# N32G41x register map
Vendor: Nsingtech Ltd.; File version: 1.0
CPU: CM4 r0p1, little endian, no MPU, no FPU, 4 interrupt priority bits
Registers are 32-bit, read-write, reset 0x0 unless marked. A register's access mark holds for its fields unless they carry their own. Offsets are from the block's base; [hi:lo] are bit positions; {n}, {i} and the like mark numbered series; 'fields as' and 'values as' point back to an identical list.

## COMP — Comparator
Base 0x40002400
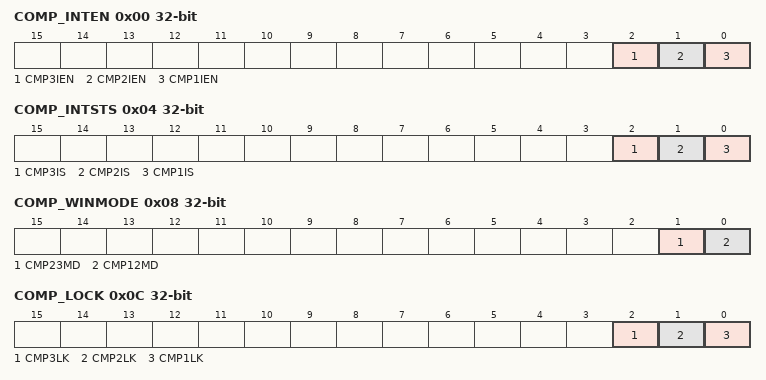
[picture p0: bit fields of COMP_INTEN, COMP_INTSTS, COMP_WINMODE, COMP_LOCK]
0x00 COMP_INTEN — COMP Interrupt Enable Register
  [2] CMP3IEN — Comparator 3 interrupt enable
  [1] CMP2IEN — Comparator 2 interrupt enable
  [0] CMP1IEN — Comparator 1 interrupt enable
0x04 COMP_INTSTS — COMP Interrupt Status Register
  [2] CMP3IS — Comparator 3 interrupt status flag, write 1 to clear
  [1] CMP2IS — Comparator 2 interrupt status flag, write 1 to clear
  [0] CMP1IS — Comparator 1 interrupt status flag, write 1 to clear
0x08 COMP_WINMODE — COMP Window Mode Register
  [1] CMP23MD — Comparator 2 and 3 window mode selection
  [0] CMP12MD — Comparator 1 and 2 window mode selection
0x0C COMP_LOCK
  [2] CMP3LK — Comparator 3 lock bit
  [1] CMP2LK — Comparator 2 lock bit
  [0] CMP1LK — Comparator 1 lock bit
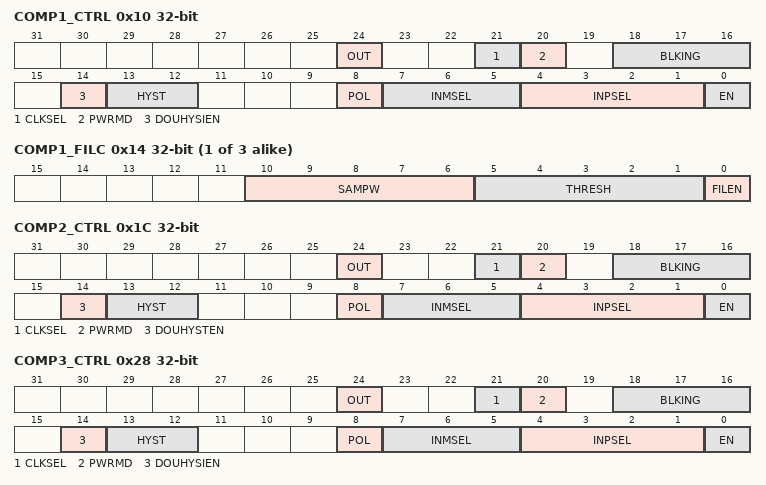
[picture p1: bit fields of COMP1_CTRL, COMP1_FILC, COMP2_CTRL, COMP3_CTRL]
0x10 COMP1_CTRL — COMP1 Control Register
  [24] OUT ro — Analog comparator output status
  [21] CLKSEL — Clock selection
  [20] PWRMD — Comparator control mode selection
  [18:16] BLKING — Blanking source selection
  [14] DOUHYSIEN — Comparator dual hysteresis selection
  [13:12] HYST — Hysteresis level selection
  [8] POL — Comparator output polarity inversion
  [7:5] INMSEL — Comparator inverting input selection
  [4:1] INPSEL — Comparator non-inverting input selection
  [0] EN — Comparator enable
{0x8+0xC*i} COMP{i}_FILC (i=1..3) — COMP{i} Filter Control Register
  [10:6] SAMPW — Low-pass filter sampling window size
  [5:1] THRESH — Low-pass filter threshold
  [0] FILEN — Filter enable
{0xC+0xC*i} COMP{i}_FILP (i=1..3) — COMP{i} Filter Clock Prescaler Register
  [15:0] CLKPSC — Low-pass filter sampling clock prescaler
0x1C COMP2_CTRL — COMP2 Control Register
  [24] OUT ro — Analog comparator output status
  [21] CLKSEL — Clock selection
  [20] PWRMD — Comparator control mode selection
  [18:16] BLKING — Blanking source selection
  [14] DOUHYSTEN — Comparator dual hysteresis selection
  [13:12] HYST — Hysteresis level selection
  [8] POL — Comparator output polarity inversion
  [7:5] INMSEL — Comparator inverting input selection
  [4:1] INPSEL — Comparator non-inverting input selection
  [0] EN — Comparator enable
0x28 COMP3_CTRL — COMP3 Control Register
  fields as COMP1_CTRL
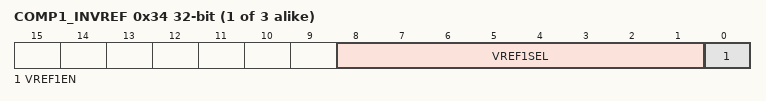
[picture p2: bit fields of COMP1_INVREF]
{0x30+4i} COMP{i}_INVREF (i=1..3) — COMP{i} Reference Input Comparison Voltage Register
  [8:1] VREF{i}SEL — Internal comparator {i} reference voltage selection
  [0] VREF{i}EN — Internal comparator {i} reference voltage enable

## OPAMP — Operational Amplifier
Base 0x40002000
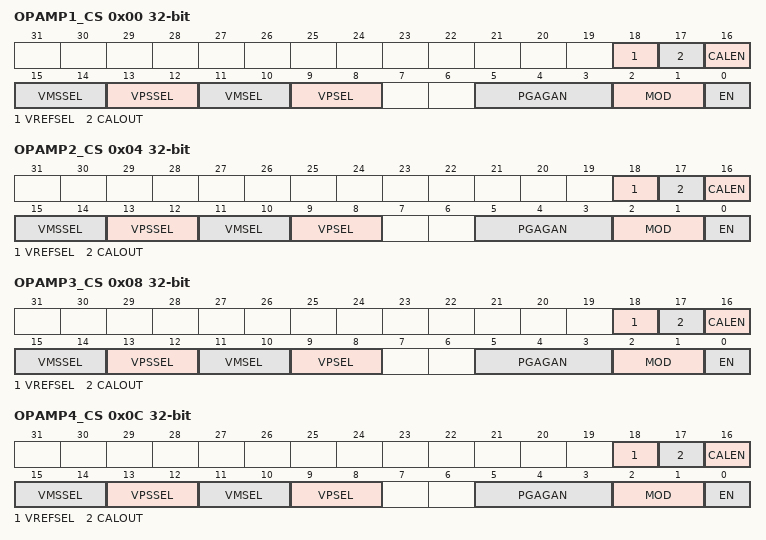
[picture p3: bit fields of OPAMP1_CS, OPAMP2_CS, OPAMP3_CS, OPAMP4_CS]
0x00 OPAMP1_CS — OPAMP1 Control Register
  [18] VREFSEL — OPAMP offset reference voltage selection
  [17] CALOUT ro — OPAMP offset calibration output
  [16] CALEN — OPAMP offset calibration enable
  [15:14] VMSSEL — Inverted input secondary selection
  [13:12] VPSSEL — Non-inverted input secondary selection
  [11:10] VMSEL — Inverted input selection
  [9:8] VPSEL — Non-inverted input selection
  [5:3] PGAGAN — PGA gain configuration
  [2:1] MOD — Work mode selection
  [0] EN — OPAMP enable
0x04 OPAMP2_CS — OPAMP2 Control Register
  fields as OPAMP1_CS
0x08 OPAMP3_CS — OPAMP3 Control Register
  fields as OPAMP1_CS
0x0C OPAMP4_CS — OPAMP4 Control Register
  fields as OPAMP1_CS
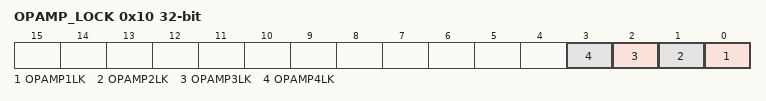
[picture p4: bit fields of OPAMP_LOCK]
0x10 OPAMP_LOCK
  [n-1] OPAMP{n}LK (n=1..4) — OPAMP{n} register lock bit

## WWDG — Window Watchdog
Base 0x40002C00
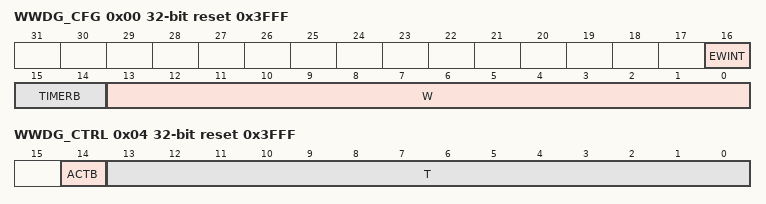
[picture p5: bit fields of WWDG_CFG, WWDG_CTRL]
0x00 WWDG_CFG reset 0x3FFF — WWDG Configuration Register
  [16] EWINT — Early wakeup interrupt enable
  [15:14] TIMERB — Timer base prescaler
  [13:0] W — Window value
0x04 WWDG_CTRL reset 0x3FFF — WWDG Control Register
  [14] ACTB — Activation bit
  [13:0] T — Counter value
0x08 WWDG_STS — WWDG Status Register
  [0] EWINTF — Early wakeup interrupt flag
